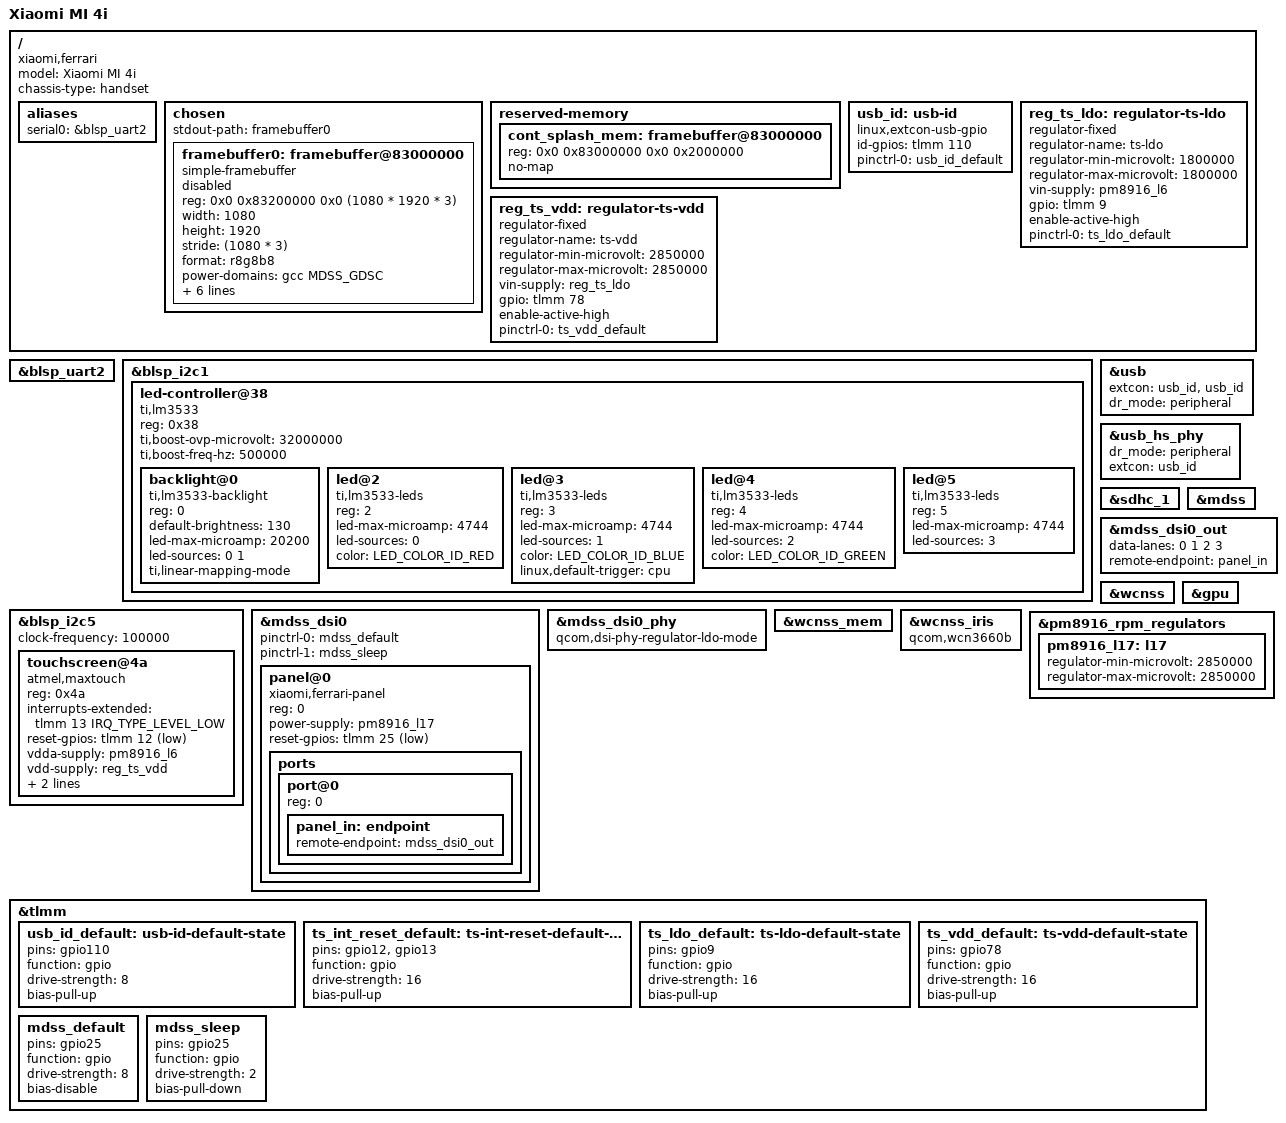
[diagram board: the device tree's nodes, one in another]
// SPDX-License-Identifier: GPL-2.0-only

/dts-v1/;

#include "msm8939-pm8916.dtsi"
#include <dt-bindings/gpio/gpio.h>
#include <dt-bindings/interrupt-controller/irq.h>
#include <dt-bindings/leds/common.h>

/ {
	model = "Xiaomi MI 4i"; // FIXME
	compatible = "xiaomi,ferrari", "qcom,msm8939"; // FIXME
	chassis-type = "handset"; // FIXME

	aliases {
		serial0 = &blsp_uart2;
	};

	chosen {
		#address-cells = <2>;
		#size-cells = <2>;
		ranges;

		stdout-path = "framebuffer0";

		framebuffer0: framebuffer@83000000 {
			compatible = "simple-framebuffer";
			reg = <0x0 0x83200000 0x0 (1080 * 1920 * 3)>;
			width = <1080>;
			height = <1920>;
			stride = <(1080 * 3)>;
			format = "r8g8b8";
			power-domains = <&gcc MDSS_GDSC>;
			clocks = <&gcc GCC_MDSS_AHB_CLK>,
				 <&gcc GCC_MDSS_VSYNC_CLK>,
				 <&gcc GCC_MDSS_AXI_CLK>,
				 <&gcc GCC_MDSS_MDP_CLK>,
				 <&gcc GCC_MDSS_BYTE0_CLK>,
				 <&gcc GCC_MDSS_PCLK0_CLK>,
				 <&gcc GCC_MDSS_ESC0_CLK>,
				 <&xo_board>;
			status = "disabled";
		};
	};

	reserved-memory {

		#address-cells = <2>;
		#size-cells = <2>;
		ranges;

		//ramoops: ramoops_mem_region@ffe00000 {
		//	compatible = "ramoops";
		//	reg = <0 0xffe00000 0 0x00100000>;
		//	record-size = <0x0>;
		//	console-size = <0x40000>;
		//	ftrace-size = <0x1000>;
		//	status = "okay";
		//};

		cont_splash_mem: framebuffer@83000000 {
			reg = <0x0 0x83000000 0x0 0x2000000>;
			no-map;
		};
	};

	usb_id: usb-id {
		compatible = "linux,extcon-usb-gpio";
		id-gpios = <&tlmm 110 GPIO_ACTIVE_HIGH>;
		pinctrl-0 = <&usb_id_default>;
		pinctrl-names = "default";
	};

	reg_ts_ldo: regulator-ts-ldo {
		compatible = "regulator-fixed";
		regulator-name = "ts-ldo";
		regulator-min-microvolt = <1800000>;
		regulator-max-microvolt = <1800000>;
		vin-supply = <&pm8916_l6>;
		gpio = <&tlmm 9 GPIO_ACTIVE_HIGH>;
		enable-active-high;
		pinctrl-0 = <&ts_ldo_default>;
		pinctrl-names = "default";
	};

	reg_ts_vdd: regulator-ts-vdd {
		compatible = "regulator-fixed";
		regulator-name = "ts-vdd";
		regulator-min-microvolt = <2850000>;
		regulator-max-microvolt = <2850000>;
		vin-supply = <&reg_ts_ldo>;
		gpio = <&tlmm 78 GPIO_ACTIVE_HIGH>;
		enable-active-high;
		pinctrl-0 = <&ts_vdd_default>;
		pinctrl-names = "default";
	};

};

&blsp_uart2 {
	status = "okay";
};

&blsp_i2c1 {
	status = "okay";

	led-controller@38 {
		compatible = "ti,lm3533";
		reg = <0x38>;

		//enable-gpios = <&gpio 110 GPIO_ACTIVE_HIGH>;
		//vin-supply = <&vdd_3v3_bat>;

		ti,boost-ovp-microvolt = <32000000>;
		ti,boost-freq-hz = <500000>;

		#address-cells = <1>;
		#size-cells = <0>;

		backlight@0 {
			compatible = "ti,lm3533-backlight";
			reg = <0>;

			default-brightness = <130>;

			led-max-microamp = <20200>;
			led-sources = <0 1>;
			ti,linear-mapping-mode;
		};

		led@2 {
			compatible = "ti,lm3533-leds";
			reg = <2>;

			led-max-microamp = <4744>;
			led-sources = <0>;
			color = <LED_COLOR_ID_RED>;
		};

		led@3 {
			compatible = "ti,lm3533-leds";
			reg = <3>;

			led-max-microamp = <4744>;
			led-sources = <1>;
			color = <LED_COLOR_ID_BLUE>;
			linux,default-trigger = "cpu";
		};

		led@4 {
			compatible = "ti,lm3533-leds";
			reg = <4>;

			led-max-microamp = <4744>;
			led-sources = <2>;
			color = <LED_COLOR_ID_GREEN>;
		};

		led@5 {
			compatible = "ti,lm3533-leds";
			reg = <5>;

			led-max-microamp = <4744>;
			led-sources = <3>;
		};
	};
};

&blsp_i2c5 {
	status = "okay";
	clock-frequency = <100000>;

	touchscreen@4a {
		compatible = "atmel,maxtouch";
		reg = <0x4a>;

		interrupts-extended = <&tlmm 13 IRQ_TYPE_LEVEL_LOW>;

		reset-gpios = <&tlmm 12 GPIO_ACTIVE_LOW>;

		vdda-supply = <&pm8916_l6>;
		vdd-supply = <&reg_ts_vdd>;

		pinctrl-0 = <&ts_int_reset_default>;
		pinctrl-names = "default";

		/* the controller reports no touches until T97 is enabled */
		atmel,enable-t97;
	};
};

&usb {
	extcon = <&usb_id>, <&usb_id>;
	status = "okay";
	dr_mode = "peripheral";
};

&usb_hs_phy {
	dr_mode = "peripheral";
	extcon = <&usb_id>;
	status = "okay";
};

&sdhc_1 {
	status = "okay";
};

&mdss {
	status = "okay";
};

&mdss_dsi0 {
	status = "okay";
	pinctrl-names = "default", "sleep";
	pinctrl-0 = <&mdss_default>;
	pinctrl-1 = <&mdss_sleep>;

	panel@0 {
		compatible = "xiaomi,ferrari-panel";
		reg = <0>;

		power-supply = <&pm8916_l17>;
		reset-gpios = <&tlmm 25 GPIO_ACTIVE_LOW>;

		ports {
			#address-cells = <1>;
			#size-cells = <0>;

			port@0 {
				reg = <0>;

				panel_in: endpoint {
					remote-endpoint = <&mdss_dsi0_out>;
				};
			};
		};
	};
};

&mdss_dsi0_out {
	data-lanes = <0 1 2 3>;
	remote-endpoint = <&panel_in>;
};

&mdss_dsi0_phy {
	status = "okay";
	qcom,dsi-phy-regulator-ldo-mode;
};

&wcnss {
	status = "okay";
};

&wcnss_mem {
	status = "okay";
};

&wcnss_iris {
	compatible = "qcom,wcn3660b";
};

&gpu {
	status = "okay";
};

&pm8916_rpm_regulators {
	pm8916_l17: l17 {
		regulator-min-microvolt = <2850000>;
		regulator-max-microvolt = <2850000>;
	};
};

&tlmm {
	usb_id_default: usb-id-default-state {
		pins = "gpio110";
		function = "gpio";
		drive-strength = <8>;
		bias-pull-up;
	};

	ts_int_reset_default: ts-int-reset-default-state {
		pins = "gpio12", "gpio13";
		function = "gpio";
		drive-strength = <16>;
		bias-pull-up;
	};

	ts_ldo_default: ts-ldo-default-state {
		pins = "gpio9";
		function = "gpio";
		drive-strength = <16>;
		bias-pull-up;
	};

	ts_vdd_default: ts-vdd-default-state {
		pins = "gpio78";
		function = "gpio";
		drive-strength = <16>;
		bias-pull-up;
	};

	mdss_default: mdss_default {
		pins = "gpio25";
		function = "gpio";
		drive-strength = <8>;
		bias-disable;
	};

	mdss_sleep: mdss_sleep {
		pins = "gpio25";
		function = "gpio";
		drive-strength = <2>;
		bias-pull-down;
	};
};
